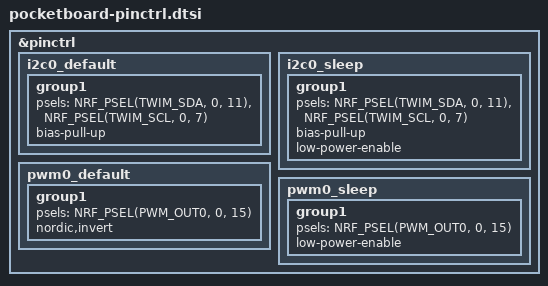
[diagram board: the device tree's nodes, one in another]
/*
 * Copyright (c) 2022 The ZMK Contributors
 * SPDX-License-Identifier: MIT
 */

&pinctrl {
    i2c0_default: i2c0_default {
        group1 {
            psels = <NRF_PSEL(TWIM_SDA, 0, 11)>,
                    <NRF_PSEL(TWIM_SCL, 0, 7)>;
            bias-pull-up;
        };
    };

    i2c0_sleep: i2c0_sleep {
        group1 {
            psels = <NRF_PSEL(TWIM_SDA, 0, 11)>,
                    <NRF_PSEL(TWIM_SCL, 0, 7)>;
            bias-pull-up;
            low-power-enable;
        };
    };

    pwm0_default: pwm0_default {
		group1 {
			psels = <NRF_PSEL(PWM_OUT0, 0, 15)>;
			nordic,invert;
		};
	};
	
	pwm0_sleep: pwm0_sleep {
		group1 {
			psels = <NRF_PSEL(PWM_OUT0, 0, 15)>;
			low-power-enable;
		};
	};
};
